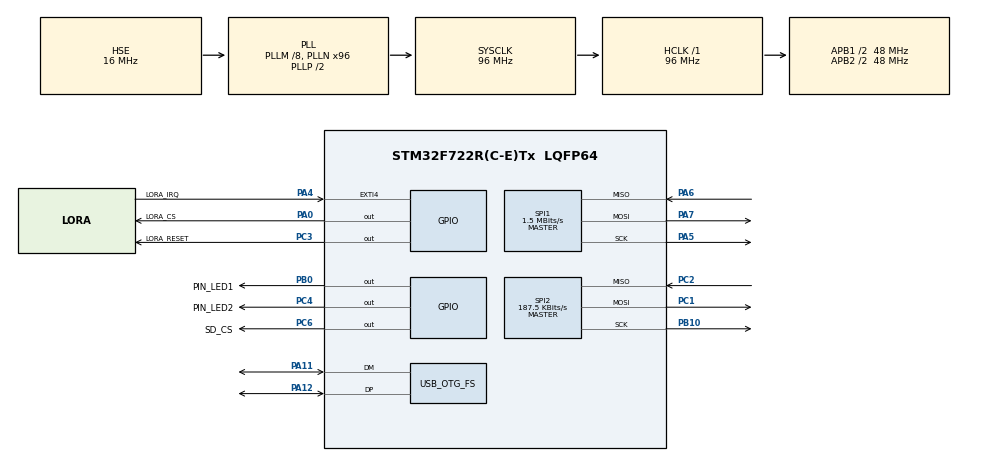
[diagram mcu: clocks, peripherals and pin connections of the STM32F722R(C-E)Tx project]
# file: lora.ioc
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Mcu.Family=STM32F7
Mcu.Name=STM32F722R(C-E)Tx
Mcu.Package=LQFP64
NVIC.EXTI4_IRQn=true\:0\:0\:false\:false\:true\:true\:true\:true
NVIC.OTG_FS_IRQn=true\:0\:0\:false\:false\:true\:false\:true\:true
NVIC.PriorityGroup=NVIC_PRIORITYGROUP_4
PA0-WKUP.GPIO_Label=LORA_CS
PA0-WKUP.GPIO_PuPd=GPIO_PULLUP
PA0-WKUP.PinState=GPIO_PIN_SET
PA0-WKUP.Signal=GPIO_Output
PA11.Mode=Device_Only
PA11.Signal=USB_OTG_FS_DM
PA12.Mode=Device_Only
PA12.Signal=USB_OTG_FS_DP
PA13.Mode=Serial_Wire
PA13.Signal=SYS_JTMS-SWDIO
PA14.Mode=Serial_Wire
PA14.Signal=SYS_JTCK-SWCLK
PA4.GPIO_Label=LORA_IRQ
PA4.GPIO_PuPd=GPIO_PULLDOWN
PA4.Signal=GPXTI4
PA5.Mode=Full_Duplex_Master
PA5.Signal=SPI1_SCK
PA6.Mode=Full_Duplex_Master
PA6.Signal=SPI1_MISO
PA7.Mode=Full_Duplex_Master
PA7.Signal=SPI1_MOSI
PB0.GPIO_Label=PIN_LED1
PB0.Signal=GPIO_Output
PB10.Mode=Full_Duplex_Master
PB10.Signal=SPI2_SCK
PC1.Mode=Full_Duplex_Master
PC1.Signal=SPI2_MOSI
PC14-OSC32_IN.Mode=LSE-External-Oscillator
PC14-OSC32_IN.Signal=RCC_OSC32_IN
PC15-OSC32_OUT.Mode=LSE-External-Oscillator
PC15-OSC32_OUT.Signal=RCC_OSC32_OUT
PC2.Mode=Full_Duplex_Master
PC2.Signal=SPI2_MISO
PC3.GPIO_Label=LORA_RESET
PC3.GPIO_PuPd=GPIO_PULLUP
PC3.Signal=GPIO_Output
PC4.GPIO_Label=PIN_LED2
PC4.Signal=GPIO_Output
PC6.GPIO_Label=SD_CS
PC6.GPIO_PuPd=GPIO_PULLUP
PC6.Signal=GPIO_Output
PH0-OSC_IN.Mode=HSE-External-Oscillator
PH0-OSC_IN.Signal=RCC_OSC_IN
PH1-OSC_OUT.Mode=HSE-External-Oscillator
PH1-OSC_OUT.Signal=RCC_OSC_OUT
ProjectManager.HeapSize=0x200
ProjectManager.StackSize=0x400
ProjectManager.TargetToolchain=STM32CubeIDE
RCC.AHBFreq_Value=96000000
RCC.APB1CLKDivider=RCC_HCLK_DIV2
RCC.APB1Freq_Value=48000000
RCC.APB1TimFreq_Value=96000000
RCC.APB2CLKDivider=RCC_HCLK_DIV2
RCC.APB2Freq_Value=48000000
RCC.APB2TimFreq_Value=96000000
RCC.CortexFreq_Value=96000000
RCC.HCLKFreq_Value=96000000
RCC.HSE_VALUE=16000000
RCC.HSI_VALUE=16000000
RCC.PLLM=8
RCC.PLLN=96
RCC.PLLQ=4
RCC.PWREXT_OverDrive=PWREXT_OverDrive_ACTIVATED
RCC.PWR_Regulator_Voltage_Scale=PWR_REGULATOR_VOLTAGE_SCALE1
RCC.SYSCLKFreq_VALUE=96000000
RCC.SYSCLKSource=RCC_SYSCLKSOURCE_PLLCLK
RCC.USBFreq_Value=48000000
RCC.VCOOutputFreq_Value=192000000
SPI1.BaudRatePrescaler=SPI_BAUDRATEPRESCALER_32
SPI1.CalculateBaudRate=1.5 MBits/s
SPI1.DataSize=SPI_DATASIZE_8BIT
SPI1.Direction=SPI_DIRECTION_2LINES
SPI1.Mode=SPI_MODE_MASTER
SPI1.VirtualType=VM_MASTER
SPI2.BaudRatePrescaler=SPI_BAUDRATEPRESCALER_256
SPI2.CalculateBaudRate=187.5 KBits/s
SPI2.DataSize=SPI_DATASIZE_8BIT
SPI2.Direction=SPI_DIRECTION_2LINES
SPI2.Mode=SPI_MODE_MASTER
SPI2.VirtualType=VM_MASTER
USB_DEVICE.CLASS_NAME_FS=CDC
USB_DEVICE.VirtualMode-CDC_FS=Cdc
USB_DEVICE.VirtualModeFS=Cdc_FS
USB_OTG_FS.VirtualMode=Device_Only
VP_FATFS_VS_Generic.Mode=User_defined
VP_USB_DEVICE_VS_USB_DEVICE_CDC_FS.Mode=CDC_FS
board=custom

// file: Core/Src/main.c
/* USER CODE BEGIN Header */
/**
  ******************************************************************************
  * @file           : main.c
  * @brief          : Main program body
  ******************************************************************************
  * @attention
  *
  * Copyright (c) 2025 STMicroelectronics.
  * All rights reserved.
  *
  * This software is licensed under terms that can be found in the LICENSE file
  * in the root directory of this software component.
  * If no LICENSE file comes with this software, it is provided AS-IS.
  *
  ******************************************************************************
  */
/* USER CODE END Header */
#include "main.h"
#include "fatfs.h"
#include "usb_device.h"

/* USER CODE BEGIN Includes */
#include <stdio.h>
#include <stdbool.h>
#include <string.h>
#include <stdarg.h>

#include "lora_fz.h"
/* USER CODE END Includes */

/* USER CODE BEGIN PTD */
uint8_t data2send[10] = {0x01, 0x02, 0x03, 0x04, 0x05, 0x06, 0x07, 0x08, 0x09, 0x0A};

/* USER CODE END PTD */

SPI_HandleTypeDef hspi1;
SPI_HandleTypeDef hspi2;

void SystemClock_Config(void);
static void MX_GPIO_Init(void);
static void MX_SPI1_Init(void);
static void MX_SPI2_Init(void);
/* USER CODE BEGIN PFP */
Role node_role = ROLE_RX; // Set the role of the device
/* USER CODE END PFP */

int main(void) {

  /* MCU Configuration--------------------------------------------------------*/

  /* Reset of all peripherals, Initializes the Flash interface and the Systick. */
  HAL_Init();

  /* Configure the system clock */
  SystemClock_Config();

  /* Initialize all configured peripherals */
  MX_GPIO_Init();
  MX_SPI1_Init();
  MX_SPI2_Init();
  MX_FATFS_Init();
  MX_USB_DEVICE_Init();
  /* USER CODE BEGIN 2 */
  // Initialize LoRa module
  if (!RF95_Init(915000000, 500, 17)) {
    while (1); // Stay here if initialization fails
  }

  if (node_role == ROLE_RX) {
    RF95_setreceiver(0); // Set to receive mode with no implicit header
  }

  /* USER CODE END 2 */

  /* Infinite loop */
  while (1) {
    if (node_role == ROLE_TX) {
      RF95_beginPacket(0, data2send, sizeof(data2send));
      RF95_sendPacket(true);
      HAL_Delay(990); // Wait for a second before sending the next packet

      if (RF95_TX_DONE_FLAG) {
        RF95_TX_DONE_FLAG = false; // Reset the TX done flag
        HAL_GPIO_WritePin(PIN_LED1_GPIO_Port, PIN_LED1_Pin, GPIO_PIN_SET); // Toggle LED to indicate TX done
        HAL_Delay(10); // Short delay to indicate TX done
        HAL_GPIO_WritePin(PIN_LED1_GPIO_Port, PIN_LED1_Pin, GPIO_PIN_RESET); // Reset LED
      }
    } else if (node_role == ROLE_RX) {
      // Handle RX logic here
      if (RF95_RX_DONE_FLAG) {
        RF95_RX_DONE_FLAG = false; // Reset the RX done flag

        int size = RF95_ReadReg(REG_RX_NB_BYTES); // Read number of bytes received
        /*
        Set FifoPtrAddr to FifoRxCurrentAddr.
        This sets the FIFO pointer to the the location of the last packet received in the FIFO.
        The payload can then be extracted by reading the RegFifo address RegNbRxBytes times.
        */
        RF95_WriteReg(REG_FIFO_ADDR_PTR, RF95_ReadReg(REG_FIFO_RX_CURRENT_ADDR));

        printf("Received packet: ");
        for (int i = 0; i < size; i++) {
          printf("%02X ", RF95_ReadReg(REG_FIFO)); // Read from FIFO and print
        }
        printf("\n");

        HAL_GPIO_WritePin(PIN_LED2_GPIO_Port, PIN_LED2_Pin, GPIO_PIN_SET); // Toggle LED to indicate RX done
        HAL_Delay(10); // Short delay to indicate RX done
        HAL_GPIO_WritePin(PIN_LED2_GPIO_Port, PIN_LED2_Pin, GPIO_PIN_RESET); // Reset LED
      }
    } else {
      // No role set, do nothing or handle as needed
    }
  }
}

void SystemClock_Config(void)
{
  RCC_OscInitTypeDef RCC_OscInitStruct = {0};
  RCC_ClkInitTypeDef RCC_ClkInitStruct = {0};

  /** Configure LSE Drive Capability
  */
  HAL_PWR_EnableBkUpAccess();

  /** Configure the main internal regulator output voltage
  */
  __HAL_RCC_PWR_CLK_ENABLE();
  __HAL_PWR_VOLTAGESCALING_CONFIG(PWR_REGULATOR_VOLTAGE_SCALE1);

  /** Initializes the RCC Oscillators according to the specified parameters
  * in the RCC_OscInitTypeDef structure.
  */
  RCC_OscInitStruct.OscillatorType = RCC_OSCILLATORTYPE_HSE;
  RCC_OscInitStruct.HSEState = RCC_HSE_ON;
  RCC_OscInitStruct.PLL.PLLState = RCC_PLL_ON;
  RCC_OscInitStruct.PLL.PLLSource = RCC_PLLSOURCE_HSE;
  RCC_OscInitStruct.PLL.PLLM = 8;
  RCC_OscInitStruct.PLL.PLLN = 96;
  RCC_OscInitStruct.PLL.PLLP = RCC_PLLP_DIV2;
  RCC_OscInitStruct.PLL.PLLQ = 4;
  if (HAL_RCC_OscConfig(&RCC_OscInitStruct) != HAL_OK)
  {
    Error_Handler();
  }

  /** Activate the Over-Drive mode
  */
  if (HAL_PWREx_EnableOverDrive() != HAL_OK)
  {
    Error_Handler();
  }

  /** Initializes the CPU, AHB and APB buses clocks
  */
  RCC_ClkInitStruct.ClockType = RCC_CLOCKTYPE_HCLK|RCC_CLOCKTYPE_SYSCLK
                              |RCC_CLOCKTYPE_PCLK1|RCC_CLOCKTYPE_PCLK2;
  RCC_ClkInitStruct.SYSCLKSource = RCC_SYSCLKSOURCE_PLLCLK;
  RCC_ClkInitStruct.AHBCLKDivider = RCC_SYSCLK_DIV1;
  RCC_ClkInitStruct.APB1CLKDivider = RCC_HCLK_DIV2;
  RCC_ClkInitStruct.APB2CLKDivider = RCC_HCLK_DIV2;

  if (HAL_RCC_ClockConfig(&RCC_ClkInitStruct, FLASH_LATENCY_3) != HAL_OK)
  {
    Error_Handler();
  }
}

static void MX_SPI1_Init(void)
{

  /* SPI1 parameter configuration*/
  hspi1.Instance = SPI1;
  hspi1.Init.Mode = SPI_MODE_MASTER;
  hspi1.Init.Direction = SPI_DIRECTION_2LINES;
  hspi1.Init.DataSize = SPI_DATASIZE_8BIT;
  hspi1.Init.CLKPolarity = SPI_POLARITY_LOW;
  hspi1.Init.CLKPhase = SPI_PHASE_1EDGE;
  hspi1.Init.NSS = SPI_NSS_SOFT;
  hspi1.Init.BaudRatePrescaler = SPI_BAUDRATEPRESCALER_32;
  hspi1.Init.FirstBit = SPI_FIRSTBIT_MSB;
  hspi1.Init.TIMode = SPI_TIMODE_DISABLE;
  hspi1.Init.CRCCalculation = SPI_CRCCALCULATION_DISABLE;
  hspi1.Init.CRCPolynomial = 7;
  hspi1.Init.CRCLength = SPI_CRC_LENGTH_DATASIZE;
  hspi1.Init.NSSPMode = SPI_NSS_PULSE_ENABLE;
  if (HAL_SPI_Init(&hspi1) != HAL_OK)
  {
    Error_Handler();
  }

}

static void MX_SPI2_Init(void)
{

  /* SPI2 parameter configuration*/
  hspi2.Instance = SPI2;
  hspi2.Init.Mode = SPI_MODE_MASTER;
  hspi2.Init.Direction = SPI_DIRECTION_2LINES;
  hspi2.Init.DataSize = SPI_DATASIZE_8BIT;
  hspi2.Init.CLKPolarity = SPI_POLARITY_LOW;
  hspi2.Init.CLKPhase = SPI_PHASE_1EDGE;
  hspi2.Init.NSS = SPI_NSS_SOFT;
  hspi2.Init.BaudRatePrescaler = SPI_BAUDRATEPRESCALER_256;
  hspi2.Init.FirstBit = SPI_FIRSTBIT_MSB;
  hspi2.Init.TIMode = SPI_TIMODE_DISABLE;
  hspi2.Init.CRCCalculation = SPI_CRCCALCULATION_DISABLE;
  hspi2.Init.CRCPolynomial = 7;
  hspi2.Init.CRCLength = SPI_CRC_LENGTH_DATASIZE;
  hspi2.Init.NSSPMode = SPI_NSS_PULSE_ENABLE;
  if (HAL_SPI_Init(&hspi2) != HAL_OK)
  {
    Error_Handler();
  }

}

static void MX_GPIO_Init(void)
{
  GPIO_InitTypeDef GPIO_InitStruct = {0};

  /* GPIO Ports Clock Enable */
  __HAL_RCC_GPIOC_CLK_ENABLE();
  __HAL_RCC_GPIOH_CLK_ENABLE();
  __HAL_RCC_GPIOA_CLK_ENABLE();
  __HAL_RCC_GPIOB_CLK_ENABLE();

  /*Configure GPIO pin Output Level */
  HAL_GPIO_WritePin(GPIOC, LORA_RESET_Pin|PIN_LED2_Pin|SD_CS_Pin, GPIO_PIN_RESET);

  /*Configure GPIO pin Output Level */
  HAL_GPIO_WritePin(LORA_CS_GPIO_Port, LORA_CS_Pin, GPIO_PIN_SET);

  /*Configure GPIO pin Output Level */
  HAL_GPIO_WritePin(PIN_LED1_GPIO_Port, PIN_LED1_Pin, GPIO_PIN_RESET);

  /*Configure GPIO pins : LORA_RESET_Pin SD_CS_Pin */
  GPIO_InitStruct.Pin = LORA_RESET_Pin|SD_CS_Pin;
  GPIO_InitStruct.Mode = GPIO_MODE_OUTPUT_PP;
  GPIO_InitStruct.Pull = GPIO_PULLUP;
  GPIO_InitStruct.Speed = GPIO_SPEED_FREQ_LOW;
  HAL_GPIO_Init(GPIOC, &GPIO_InitStruct);

  /*Configure GPIO pin : LORA_CS_Pin */
  GPIO_InitStruct.Pin = LORA_CS_Pin;
  GPIO_InitStruct.Mode = GPIO_MODE_OUTPUT_PP;
  GPIO_InitStruct.Pull = GPIO_PULLUP;
  GPIO_InitStruct.Speed = GPIO_SPEED_FREQ_LOW;
  HAL_GPIO_Init(LORA_CS_GPIO_Port, &GPIO_InitStruct);

  /*Configure GPIO pin : LORA_IRQ_Pin */
  GPIO_InitStruct.Pin = LORA_IRQ_Pin;
  GPIO_InitStruct.Mode = GPIO_MODE_IT_RISING;
  GPIO_InitStruct.Pull = GPIO_PULLDOWN;
  HAL_GPIO_Init(LORA_IRQ_GPIO_Port, &GPIO_InitStruct);

  /*Configure GPIO pin : PIN_LED2_Pin */
  GPIO_InitStruct.Pin = PIN_LED2_Pin;
  GPIO_InitStruct.Mode = GPIO_MODE_OUTPUT_PP;
  GPIO_InitStruct.Pull = GPIO_NOPULL;
  GPIO_InitStruct.Speed = GPIO_SPEED_FREQ_LOW;
  HAL_GPIO_Init(PIN_LED2_GPIO_Port, &GPIO_InitStruct);

  /*Configure GPIO pin : PIN_LED1_Pin */
  GPIO_InitStruct.Pin = PIN_LED1_Pin;
  GPIO_InitStruct.Mode = GPIO_MODE_OUTPUT_PP;
  GPIO_InitStruct.Pull = GPIO_NOPULL;
  GPIO_InitStruct.Speed = GPIO_SPEED_FREQ_LOW;
  HAL_GPIO_Init(PIN_LED1_GPIO_Port, &GPIO_InitStruct);

  /* EXTI interrupt init*/
  HAL_NVIC_SetPriority(EXTI4_IRQn, 0, 0);
  HAL_NVIC_EnableIRQ(EXTI4_IRQn);

}

void Error_Handler(void)
{
  __disable_irq();
  while (1)
  {
  }
}
